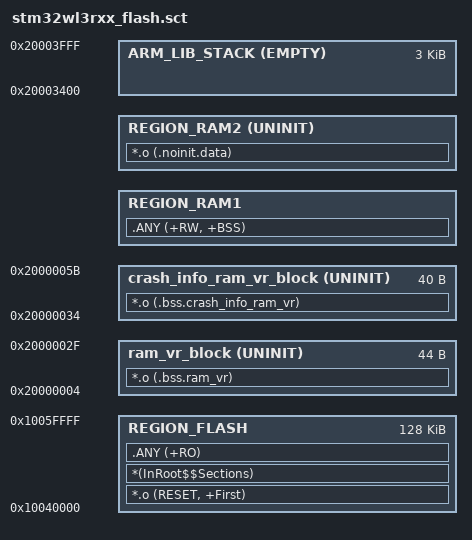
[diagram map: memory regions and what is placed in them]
#!armclang -E --target=arm-arm-none-eabi -mcpu=cortex-m0plus -xc
/*******************************************************************************
* STM32WL3x generic linker file for KEIL
* Main linker variables to control it are:
*
* MEMORY_FLASH_APP_SIZE: define the size of the application in case not all the flash is needed.
* Default value is: 128KB
*
* MEMORY_FLASH_APP_OFFSET: define the offset of the application.
* Default value is: 0 offset
*
* MEMORY_RAM_APP_OFFSET: define the offset in RAM from which variables can be
* allocated.
* 
*******************************************************************************/

/*******************************************************************************
* Memory Definitions
*******************************************************************************/
/*
STM32WL3x memory map
+-----------------------+ 0x20003FFF
|  RAM (16K)            |
+-----------------------+ 0x20000000
|                       |
|                       |
+-----------------------+ 0x1005FFFF
|                       |
|  FLASH (128K)         |
+-----------------------+ 0x10040000
|                       |
+-----------------------| 0x100017FF
|   ROM (6K)            |
+-----------------------+ 0x10000000
*/

#define _MEMORY_RAM_BEGIN_    0x20000000
#define _MEMORY_RAM_SIZE_     0x04000          /* 16KB  */
#define _MEMORY_RAM_END_      0x20003FFF

#define _MEMORY_FLASH_BEGIN_  0x10040000  
#define _MEMORY_FLASH_SIZE_   0x20000          /* 128KB */ 
#define _MEMORY_FLASH_END_    0x1005FFFF  

#define _MEMORY_ROM_BEGIN_    0x10000000    
#define _MEMORY_ROM_SIZE_     0x1800           /* 6KB */ 
#define _MEMORY_ROM_END_      0x100017FF  

#ifndef MEMORY_FLASH_APP_OFFSET
#define MEMORY_FLASH_APP_OFFSET  (0)
#endif

#ifndef MEMORY_FLASH_APP_SIZE
#define MEMORY_FLASH_APP_SIZE  (_MEMORY_FLASH_SIZE_ - MEMORY_FLASH_APP_OFFSET)
#endif

LR_IROM1 (_MEMORY_FLASH_BEGIN_+MEMORY_FLASH_APP_OFFSET) _MEMORY_FLASH_SIZE_  {    ; load region size_region
  REGION_FLASH (_MEMORY_FLASH_BEGIN_ + MEMORY_FLASH_APP_OFFSET) (MEMORY_FLASH_APP_SIZE)  {  ; load address = execution address
   *.o (RESET, +First)
   *(InRoot$$Sections)
   .ANY (+RO)
  }
  ram_vr_block 0x20000004 UNINIT 0x2C {
   *.o (.bss.ram_vr)
  }
  crash_info_ram_vr_block 0x20000034 UNINIT 40 {  
  *.o (.bss.crash_info_ram_vr)
  }
  
#ifndef MEMORY_RAM_APP_OFFSET
  REGION_RAM1 +0  {  ; RW data
   .ANY (+RW, +BSS)
  }
#else
  REGION_RAM1 (_MEMORY_RAM_BEGIN_ + MEMORY_RAM_APP_OFFSET) {  ; RW data
   .ANY (+RW, +BSS)
  }
#endif
  REGION_RAM2 +0 UNINIT  {  ; RW data not initialized
   *.o (.noinit.data)
  }
  ARM_LIB_STACK (_MEMORY_RAM_END_+1) EMPTY -0xC00 { }
}
